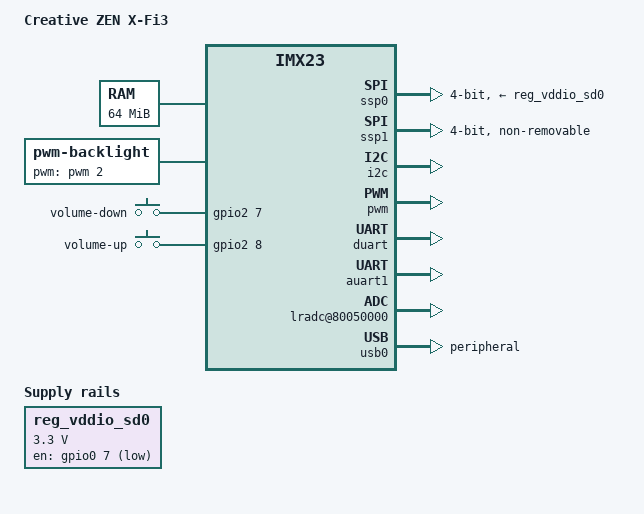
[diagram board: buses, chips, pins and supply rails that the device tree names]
/dts-v1/;
#include "imx23.dtsi"
/ {
	model = "Creative ZEN X-Fi3";
	compatible = "creative,x-fi3", "fsl,imx23";
	memory@40000000 {
		device_type = "memory";
		reg = <0x40000000 0x04000000>;
	};
	apb@80000000 {
		apbh@80000000 {
			ssp0: spi@80010000 {
				compatible = "fsl,imx23-mmc";
				pinctrl-names = "default";
				pinctrl-0 = <&mmc0_4bit_pins_a &mmc0_pins_fixup>;
				bus-width = <4>;
				vmmc-supply = <&reg_vddio_sd0>;
				cd-inverted;
				status = "okay";
			};
			ssp1: spi@80034000 {
				compatible = "fsl,imx23-mmc";
				pinctrl-names = "default";
				pinctrl-0 = <&mmc1_4bit_pins_a>;
				bus-width = <4>;
				non-removable;
				status = "okay";
			};
			pinctrl@80018000 {
				pinctrl-names = "default";
				pinctrl-0 = <&hog_pins_a>;
				hog_pins_a: hog@0 {
					reg = <0>;
					fsl,pinmux-ids = <
						MX23_PAD_GPMI_D07__GPIO_0_7
					>;
					fsl,drive-strength = <0>;
					fsl,voltage = <1>;
					fsl,pull-up = <0>;
				};
				key_pins_a: keys@0 {
					reg = <0>;
					fsl,pinmux-ids = <
						MX23_PAD_ROTARYA__GPIO_2_7
						MX23_PAD_ROTARYB__GPIO_2_8
					>;
					fsl,drive-strength = <0>;
					fsl,voltage = <1>;
					fsl,pull-up = <1>;
				};
			};
		};
		apbx@80040000 {
			i2c: i2c@80058000 {
				pinctrl-names = "default";
				pinctrl-0 = <&i2c_pins_a>;
				status = "okay";
			};
			pwm: pwm@80064000 {
				pinctrl-names = "default";
				pinctrl-0 = <&pwm2_pins_a>;
				status = "okay";
			};
			duart: serial@80070000 {
				pinctrl-names = "default";
				pinctrl-0 = <&duart_pins_a>;
				status = "okay";
			};
			auart1: serial@8006e000 {
				pinctrl-names = "default";
				pinctrl-0 = <&auart1_2pins_a>;
				status = "okay";
			};
			usbphy0: usbphy@8007c000 {
				status = "okay";
			};
			lradc@80050000 {
				status = "okay";
			};
		};
	};
	ahb@80080000 {
		usb0: usb@80080000 {
			dr_mode = "peripheral";
			status = "okay";
		};
	};
	reg_vddio_sd0: regulator-vddio-sd0 {
		compatible = "regulator-fixed";
		regulator-name = "vddio-sd0";
		regulator-min-microvolt = <3300000>;
		regulator-max-microvolt = <3300000>;
		gpio = <&gpio0 7 0>;
	};
	backlight {
		compatible = "pwm-backlight";
		pwms = <&pwm 2 5000000>;
		brightness-levels = <0 4 8 16 32 64 128 255>;
		default-brightness-level = <6>;
	};
	gpio-keys {
		compatible = "gpio-keys";
		pinctrl-names = "default";
		pinctrl-0 = <&key_pins_a>;
		key-voldown {
			label = "volume-down";
			linux,code = <114>;
			gpios = <&gpio2 7 0>;
			debounce-interval = <20>;
		};
		key-volup {
			label = "volume-up";
			linux,code = <115>;
			gpios = <&gpio2 8 0>;
			debounce-interval = <20>;
		};
	};
};
